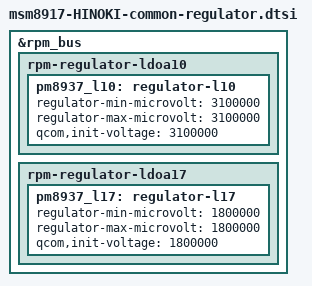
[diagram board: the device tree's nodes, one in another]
/*
 * This software is contributed or developed by KYOCERA Corporation.
 * (C) 2019 KYOCERA Corporation
 *
 * This program is free software; you can redistribute it and/or modify
 * it under the terms of the GNU General Public License version 2 and
 * only version 2 as published by the Free Software Foundation.
 *
 * This program is distributed in the hope that it will be useful,
 * but WITHOUT ANY WARRANTY; without even the implied warranty of
 * MERCHANTABILITY or FITNESS FOR A PARTICULAR PURPOSE.  See the
 * GNU General Public License for more details.
 */

&rpm_bus {

	rpm-regulator-ldoa10 {
		status = "okay";
		pm8937_l10: regulator-l10 {
			regulator-min-microvolt = <3100000>;
			regulator-max-microvolt = <3100000>;
			qcom,init-voltage = <3100000>;
			status = "okay";
		};
	};

	rpm-regulator-ldoa17 {
		status = "okay";
		pm8937_l17: regulator-l17 {
			regulator-min-microvolt = <1800000>;
			regulator-max-microvolt = <1800000>;
			qcom,init-voltage = <1800000>;
			status = "okay";
		};
	};

};

